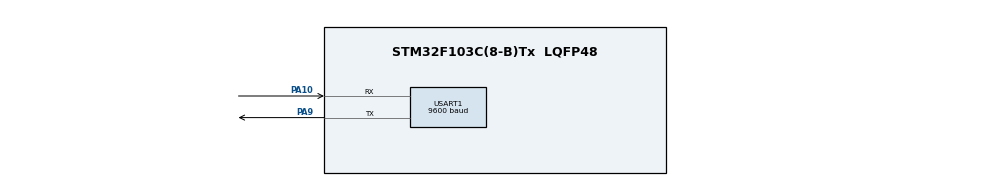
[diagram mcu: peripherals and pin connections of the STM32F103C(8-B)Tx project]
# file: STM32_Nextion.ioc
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Dma.Request0=USART1_RX
Dma.USART1_RX.0.Direction=DMA_PERIPH_TO_MEMORY
Dma.USART1_RX.0.Instance=DMA1_Channel5
Dma.USART1_RX.0.MemDataAlignment=DMA_MDATAALIGN_BYTE
Dma.USART1_RX.0.MemInc=DMA_MINC_ENABLE
Dma.USART1_RX.0.Mode=DMA_CIRCULAR
Dma.USART1_RX.0.PeriphDataAlignment=DMA_PDATAALIGN_BYTE
Dma.USART1_RX.0.PeriphInc=DMA_PINC_DISABLE
Dma.USART1_RX.0.Priority=DMA_PRIORITY_MEDIUM
Mcu.Family=STM32F1
Mcu.Name=STM32F103C(8-B)Tx
Mcu.Package=LQFP48
NVIC.DMA1_Channel5_IRQn=true\:5\:0\:true\:false\:true\:false\:true
NVIC.PriorityGroup=NVIC_PRIORITYGROUP_4
NVIC.USART1_IRQn=true\:5\:0\:true\:false\:true\:true\:true
PA10.Mode=Asynchronous
PA10.Signal=USART1_RX
PA13.Mode=Serial_Wire
PA13.Signal=SYS_JTMS-SWDIO
PA14.Mode=Serial_Wire
PA14.Signal=SYS_JTCK-SWCLK
PA9.Mode=Asynchronous
PA9.Signal=USART1_TX
PD0-OSC_IN.Mode=HSE-External-Oscillator
PD0-OSC_IN.Signal=RCC_OSC_IN
PD1-OSC_OUT.Mode=HSE-External-Oscillator
PD1-OSC_OUT.Signal=RCC_OSC_OUT
ProjectManager.HeapSize=0x200
ProjectManager.StackSize=0x400
ProjectManager.TargetToolchain=TrueSTUDIO
RCC.AHBFreq_Value=72000000
RCC.APB1CLKDivider=RCC_HCLK_DIV2
RCC.APB1Freq_Value=36000000
RCC.APB1TimFreq_Value=72000000
RCC.APB2Freq_Value=72000000
RCC.APB2TimFreq_Value=72000000
RCC.HCLKFreq_Value=72000000
RCC.PLLMUL=RCC_PLL_MUL9
RCC.PLLSourceVirtual=RCC_PLLSOURCE_HSE
RCC.SYSCLKFreq_VALUE=72000000
RCC.SYSCLKSource=RCC_SYSCLKSOURCE_PLLCLK
RCC.USBFreq_Value=72000000
USART1.BaudRate=9600
USART1.VirtualMode=VM_ASYNC
board=custom

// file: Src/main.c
/* USER CODE BEGIN Header */
/**
 ******************************************************************************
 * @file           : main.c
 * @brief          : Main program body
 ******************************************************************************
 * @attention
 *
 * <h2><center>&copy; Copyright (c) 2019 STMicroelectronics.
 * All rights reserved.</center></h2>
 *
 * This software component is licensed by ST under BSD 3-Clause license,
 * the "License"; You may not use this file except in compliance with the
 * License. You may obtain a copy of the License at:
 *                        opensource.org/licenses/BSD-3-Clause
 *
 ******************************************************************************
 */
/* USER CODE END Header */

#include "main.h"
#include "dma.h"
#include "usart.h"
#include "gpio.h"

/* USER CODE BEGIN Includes */
#include "string.h"
#include "nextion.h"

/* USER CODE END Includes */

/* USER CODE BEGIN PV */
/* Private variables ---------------------------------------------------------*/
uint8_t Current_Page = 0;
uint8_t Page_RCV_Flag = 0;

/* USER CODE END PV */

void SystemClock_Config(void);
/* USER CODE BEGIN PFP */
/* Private function prototypes -----------------------------------------------*/

/* USER CODE END PFP */

/* USER CODE BEGIN 0 */

void BTN_Setting_Pressed()
    {
    Nextion_Set_Text("b0", "Pressed");
    }
void BTN_Setting_Released()
    {
    Nextion_Set_Text("b0", "Released");
    }

void Page_0_Touched()
    {
    //Nextion_Hide_Object("b0",true);
    uint32_t timeout = 0xFFFF;
    Page_RCV_Flag = 0;
    Nextion_Get_Current_Page();
    while (!Page_RCV_Flag && --timeout)
	{
	}

    if (timeout)
	{
	if (Current_Page == 0)
	    {
	    Nextion_Set_BCK_Colour("b0", 63488);
	    }
	}
    }

void Page_0_Released()
    {
    //Nextion_Hide_Object("b0",false);
    static Page_0_Touch_Count = 0;
    uint32_t timeout = 0xFFFF;
    Page_RCV_Flag = 0;
    Nextion_Get_Current_Page();
    while (!Page_RCV_Flag && --timeout)
	{
	}

    if (timeout)
	{
	if (Current_Page == 0)
	    {
	    Nextion_Set_BCK_Colour("b0", 48631);
	    }
	}

    Page_0_Touch_Count++;

    if (Page_0_Touch_Count == 10)
	{
	Page_0_Touch_Count = 0;
	Nextion_Send_Command("page 4");
	}
    }

void Page_1_Touched()
    {
    //Nextion_Hide_Object("b0",true);

    uint32_t timeout = 0xFFFF;
    Page_RCV_Flag = 0;
    Nextion_Get_Current_Page();
    while (!Page_RCV_Flag && --timeout)
	{
	}

    if (timeout)
	{
	if (Current_Page == 1)
	    {
	    Nextion_Set_BCK_Colour("b0", 63488);
	    }
	}

    Nextion_Backlight_Brightness(50, 0);
    }

void Page_1_Released()
    {
    //Nextion_Hide_Object("b0",false);
    uint32_t timeout = 0xFFFF;
    Page_RCV_Flag = 0;
    Nextion_Get_Current_Page();
    while (!Page_RCV_Flag && --timeout)
	{
	}

    if (timeout)
	{
	if (Current_Page == 1)
	    {
	    Nextion_Set_BCK_Colour("b0", 48631);
	    }
	}

    Nextion_Backlight_Brightness(80, 0);
    }

void Nextion_RX_Page_ID_Callback(uint8_t Page_ID)
    {
    Page_RCV_Flag = 0;
    Current_Page = Page_ID;
    }

void Nextion_RX_String_Callback(const char* str)
    {

    }

void Nextion_RX_Number_Callback(uint32_t Number)
    {

    }

void Nextion_CMD_Finished_Callback()
    {

    }

/* USER CODE END 0 */

int main(void)
    {

    /* MCU Configuration--------------------------------------------------------*/

    /* Reset of all peripherals, Initializes the Flash interface and the Systick. */
    HAL_Init();

    /* Configure the system clock */
    SystemClock_Config();

    /* Initialize all configured peripherals */
    MX_GPIO_Init();
    MX_DMA_Init();
    MX_USART1_UART_Init();
    /* USER CODE BEGIN 2 */

    Nextion_Init();

    Nextion_Object_t Page_0_Object;

    Page_0_Object.Push_Callback = &Page_0_Touched;
    Page_0_Object.Pop_Callback = &Page_0_Released;
    Page_0_Object.Component_ID = 0;
    Page_0_Object.Page_ID = 0;
    Page_0_Object.Name = "page 0";

    Nextion_Add_Object(&Page_0_Object);

    Nextion_Object_t Page_1_Object;

    Page_1_Object.Push_Callback = &Page_1_Touched;
    Page_1_Object.Pop_Callback = &Page_1_Released;
    Page_1_Object.Component_ID = 0;
    Page_1_Object.Page_ID = 1;
    Page_1_Object.Name = "page 1";

    Nextion_Add_Object(&Page_1_Object);

    Nextion_Object_t BTN_Setting;

    BTN_Setting.Push_Callback = NULL;
    BTN_Setting.Pop_Callback = &BTN_Setting_Released;
    BTN_Setting.Component_ID = 6;
    BTN_Setting.Page_ID = 0;
    BTN_Setting.Name = "b0";

    Nextion_Add_Object(&BTN_Setting);

    /* USER CODE END 2 */

    /* Infinite loop */
    while (1)
	{

	/* USER CODE BEGIN 3 */

	Nextion_Loop();

	}
    /* USER CODE END 3 */
    }

void SystemClock_Config(void)
    {
    RCC_OscInitTypeDef RCC_OscInitStruct =
	{
	0
	};
    RCC_ClkInitTypeDef RCC_ClkInitStruct =
	{
	0
	};

    /** Initializes the CPU, AHB and APB busses clocks
     */
    RCC_OscInitStruct.OscillatorType = RCC_OSCILLATORTYPE_HSE;
    RCC_OscInitStruct.HSEState = RCC_HSE_ON;
    RCC_OscInitStruct.HSEPredivValue = RCC_HSE_PREDIV_DIV1;
    RCC_OscInitStruct.HSIState = RCC_HSI_ON;
    RCC_OscInitStruct.PLL.PLLState = RCC_PLL_ON;
    RCC_OscInitStruct.PLL.PLLSource = RCC_PLLSOURCE_HSE;
    RCC_OscInitStruct.PLL.PLLMUL = RCC_PLL_MUL9;
    if (HAL_RCC_OscConfig(&RCC_OscInitStruct) != HAL_OK)
	{
	Error_Handler();
	}
    /** Initializes the CPU, AHB and APB busses clocks
     */
    RCC_ClkInitStruct.ClockType = RCC_CLOCKTYPE_HCLK | RCC_CLOCKTYPE_SYSCLK
	    | RCC_CLOCKTYPE_PCLK1 | RCC_CLOCKTYPE_PCLK2;
    RCC_ClkInitStruct.SYSCLKSource = RCC_SYSCLKSOURCE_PLLCLK;
    RCC_ClkInitStruct.AHBCLKDivider = RCC_SYSCLK_DIV1;
    RCC_ClkInitStruct.APB1CLKDivider = RCC_HCLK_DIV2;
    RCC_ClkInitStruct.APB2CLKDivider = RCC_HCLK_DIV1;

    if (HAL_RCC_ClockConfig(&RCC_ClkInitStruct, FLASH_LATENCY_2) != HAL_OK)
	{
	Error_Handler();
	}
    }

void Error_Handler(void)
    {
    while (1)
	{
	}
    }

/************************ (C) COPYRIGHT STMicroelectronics *****END OF FILE****/
